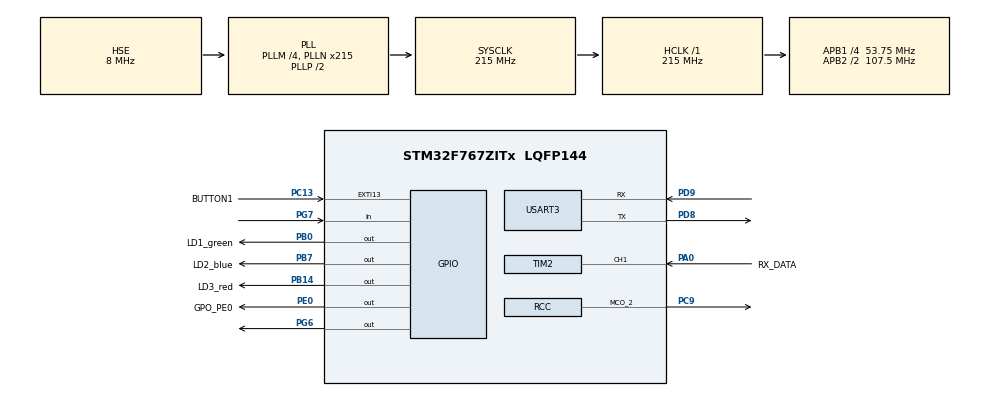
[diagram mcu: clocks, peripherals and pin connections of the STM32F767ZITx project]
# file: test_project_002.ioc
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CORTEX_M7.ART_ACCLERATOR_ENABLE=0
CORTEX_M7.CPU_ICache=Disabled
CORTEX_M7.FlashInterface=TCM_Enabled
CORTEX_M7.PREFETCH_ENABLE=0
Dma.Request0=TIM2_CH1
Dma.TIM2_CH1.0.Direction=DMA_PERIPH_TO_MEMORY
Dma.TIM2_CH1.0.FIFOMode=DMA_FIFOMODE_ENABLE
Dma.TIM2_CH1.0.FIFOThreshold=DMA_FIFO_THRESHOLD_HALFFULL
Dma.TIM2_CH1.0.Instance=DMA1_Stream5
Dma.TIM2_CH1.0.MemBurst=DMA_MBURST_SINGLE
Dma.TIM2_CH1.0.MemDataAlignment=DMA_MDATAALIGN_WORD
Dma.TIM2_CH1.0.MemInc=DMA_MINC_ENABLE
Dma.TIM2_CH1.0.Mode=DMA_NORMAL
Dma.TIM2_CH1.0.PeriphBurst=DMA_PBURST_SINGLE
Dma.TIM2_CH1.0.PeriphDataAlignment=DMA_PDATAALIGN_WORD
Dma.TIM2_CH1.0.PeriphInc=DMA_PINC_DISABLE
Dma.TIM2_CH1.0.Priority=DMA_PRIORITY_VERY_HIGH
Mcu.Family=STM32F7
Mcu.Name=STM32F767ZITx
Mcu.Package=LQFP144
NVIC.DMA1_Stream5_IRQn=true\:0\:0\:false\:false\:true\:false\:true
NVIC.PriorityGroup=NVIC_PRIORITYGROUP_4
NVIC.TIM1_UP_TIM10_IRQn=true\:0\:0\:false\:false\:true\:false\:true
NVIC.TimeBase=TIM1_UP_TIM10_IRQn
NVIC.TimeBaseIP=TIM1
PA0/WKUP.GPIO_Label=RX_DATA
PA0/WKUP.GPIO_Speed=GPIO_SPEED_FREQ_VERY_HIGH
PA0/WKUP.Signal=S_TIM2_CH1_ETR
PA1.GPIO_Mode=GPIO_MODE_AF_PP
PA1.GPIO_PuPd=GPIO_NOPULL
PA1.GPIO_Speed=GPIO_SPEED_FREQ_VERY_HIGH
PA1.Signal=ETH_REF_CLK
PA10.GPIO_Mode=GPIO_MODE_AF_PP
PA10.GPIO_PuPd=GPIO_NOPULL
PA10.GPIO_Speed=GPIO_SPEED_FREQ_VERY_HIGH
PA10.Signal=USB_OTG_FS_ID
PA11.GPIO_Mode=GPIO_MODE_AF_PP
PA11.GPIO_PuPd=GPIO_NOPULL
PA11.GPIO_Speed=GPIO_SPEED_FREQ_VERY_HIGH
PA11.Signal=USB_OTG_FS_DM
PA12.GPIO_Mode=GPIO_MODE_AF_PP
PA12.GPIO_PuPd=GPIO_NOPULL
PA12.GPIO_Speed=GPIO_SPEED_FREQ_VERY_HIGH
PA12.Signal=USB_OTG_FS_DP
PA13.Mode=Serial_Wire
PA13.Signal=SYS_JTMS-SWDIO
PA14.Mode=Serial_Wire
PA14.Signal=SYS_JTCK-SWCLK
PA2.GPIO_Mode=GPIO_MODE_AF_PP
PA2.GPIO_PuPd=GPIO_NOPULL
PA2.GPIO_Speed=GPIO_SPEED_FREQ_VERY_HIGH
PA2.Signal=ETH_MDIO
PA7.GPIO_Mode=GPIO_MODE_AF_PP
PA7.GPIO_PuPd=GPIO_NOPULL
PA7.GPIO_Speed=GPIO_SPEED_FREQ_VERY_HIGH
PA7.Signal=ETH_CRS_DV
PA8.GPIO_Mode=GPIO_MODE_AF_PP
PA8.GPIO_PuPd=GPIO_NOPULL
PA8.GPIO_Speed=GPIO_SPEED_FREQ_VERY_HIGH
PA8.Signal=USB_OTG_FS_SOF
PA9.GPIO_Mode=GPIO_MODE_INPUT
PA9.GPIO_PuPd=GPIO_NOPULL
PA9.Signal=USB_OTG_FS_VBUS
PB0.GPIO_Label=LD1_green
PB0.GPIO_ModeDefaultOutputPP=GPIO_MODE_OUTPUT_PP
PB0.GPIO_PuPd=GPIO_NOPULL
PB0.GPIO_Speed=GPIO_SPEED_FREQ_LOW
PB0.PinState=GPIO_PIN_RESET
PB0.Signal=GPIO_Output
PB13.GPIO_Mode=GPIO_MODE_AF_PP
PB13.GPIO_PuPd=GPIO_NOPULL
PB13.GPIO_Speed=GPIO_SPEED_FREQ_VERY_HIGH
PB13.Signal=ETH_TXD1
PB14.GPIO_Label=LD3_red
PB14.GPIO_ModeDefaultOutputPP=GPIO_MODE_OUTPUT_PP
PB14.GPIO_PuPd=GPIO_NOPULL
PB14.GPIO_Speed=GPIO_SPEED_FREQ_LOW
PB14.PinState=GPIO_PIN_RESET
PB14.Signal=GPIO_Output
PB3.Signal=SYS_JTDO-SWO
PB7.GPIO_FM7=__NULL
PB7.GPIO_Label=LD2_blue
PB7.GPIO_ModeDefaultOutputPP=GPIO_MODE_OUTPUT_PP
PB7.GPIO_PuPd=GPIO_NOPULL
PB7.GPIO_Speed=GPIO_SPEED_FREQ_LOW
PB7.PinState=GPIO_PIN_RESET
PB7.Signal=GPIO_Output
PC1.GPIO_Mode=GPIO_MODE_AF_PP
PC1.GPIO_PuPd=GPIO_NOPULL
PC1.GPIO_Speed=GPIO_SPEED_FREQ_VERY_HIGH
PC1.Signal=ETH_MDC
PC13.GPIO_Label=BUTTON1
PC13.GPIO_ModeDefaultEXTI=GPIO_MODE_IT_RISING
PC13.GPIO_PuPd=GPIO_NOPULL
PC13.Signal=GPXTI13
PC14/OSC32_IN.Mode=LSE-External-Oscillator
PC14/OSC32_IN.Signal=RCC_OSC32_IN
PC15/OSC32_OUT.Mode=LSE-External-Oscillator
PC15/OSC32_OUT.Signal=RCC_OSC32_OUT
PC4.GPIO_Mode=GPIO_MODE_AF_PP
PC4.GPIO_PuPd=GPIO_NOPULL
PC4.GPIO_Speed=GPIO_SPEED_FREQ_VERY_HIGH
PC4.Signal=ETH_RXD0
PC5.GPIO_Mode=GPIO_MODE_AF_PP
PC5.GPIO_PuPd=GPIO_NOPULL
PC5.GPIO_Speed=GPIO_SPEED_FREQ_VERY_HIGH
PC5.Signal=ETH_RXD1
PC9.Mode=Clock-out-2
PC9.Signal=RCC_MCO_2
PD8.GPIO_ModeDefaultPP=GPIO_MODE_AF_PP
PD8.GPIO_PuPd=GPIO_NOPULL
PD8.GPIO_Speed=GPIO_SPEED_FREQ_VERY_HIGH
PD8.Mode=Asynchronous
PD8.Signal=USART3_TX
PD9.GPIO_ModeDefaultPP=GPIO_MODE_AF_PP
PD9.GPIO_PuPd=GPIO_NOPULL
PD9.GPIO_Speed=GPIO_SPEED_FREQ_VERY_HIGH
PD9.Mode=Asynchronous
PD9.Signal=USART3_RX
PE0.GPIO_Label=GPO_PE0
PE0.GPIO_ModeDefaultOutputPP=GPIO_MODE_OUTPUT_PP
PE0.GPIO_PuPd=GPIO_NOPULL
PE0.GPIO_Speed=GPIO_SPEED_FREQ_VERY_HIGH
PE0.PinState=GPIO_PIN_RESET
PE0.Signal=GPIO_Output
PG11.GPIO_Mode=GPIO_MODE_AF_PP
PG11.GPIO_PuPd=GPIO_NOPULL
PG11.GPIO_Speed=GPIO_SPEED_FREQ_VERY_HIGH
PG11.Signal=ETH_TX_EN
PG13.GPIO_Mode=GPIO_MODE_AF_PP
PG13.GPIO_PuPd=GPIO_NOPULL
PG13.GPIO_Speed=GPIO_SPEED_FREQ_VERY_HIGH
PG13.Signal=ETH_TXD0
PG6.GPIO_ModeDefaultOutputPP=GPIO_MODE_OUTPUT_PP
PG6.GPIO_PuPd=GPIO_NOPULL
PG6.GPIO_Speed=GPIO_SPEED_FREQ_LOW
PG6.PinState=GPIO_PIN_RESET
PG6.Signal=GPIO_Output
PG7.GPIO_Mode=GPIO_MODE_INPUT
PG7.GPIO_PuPd=GPIO_NOPULL
PG7.Signal=GPIO_Input
PH0/OSC_IN.Mode=HSE-External-Clock-Source
PH0/OSC_IN.Signal=RCC_OSC_IN
PH1/OSC_OUT.Mode=HSE-External-Clock-Source
PH1/OSC_OUT.Signal=RCC_OSC_OUT
ProjectManager.HeapSize=0x200
ProjectManager.StackSize=0x400
ProjectManager.TargetToolchain=STM32CubeIDE
RCC.AHBFreq_Value=215000000
RCC.APB1CLKDivider=RCC_HCLK_DIV4
RCC.APB1Freq_Value=53750000
RCC.APB1TimFreq_Value=107500000
RCC.APB2CLKDivider=RCC_HCLK_DIV2
RCC.APB2Freq_Value=107500000
RCC.APB2TimFreq_Value=215000000
RCC.CortexFreq_Value=215000000
RCC.HCLKFreq_Value=215000000
RCC.HSE_VALUE=8000000
RCC.HSI_VALUE=16000000
RCC.PLL48CLockSelection=RCC_CLK48SOURCE_PLLSAIP
RCC.PLLM=4
RCC.PLLN=215
RCC.PLLSAIN=96
RCC.PLLSAIP=RCC_PLLSAIP_DIV4
RCC.PLLSourceVirtual=RCC_PLLSOURCE_HSE
RCC.RCC_MCO2Source=RCC_MCO2SOURCE_PLLI2SCLK
RCC.SYSCLKFreq_VALUE=215000000
RCC.SYSCLKSource=RCC_SYSCLKSOURCE_PLLCLK
RCC.USBFreq_Value=48000000
RCC.VCOOutputFreq_Value=430000000
SH.S_TIM2_CH1_ETR.0=TIM2_CH1,Input_Capture1_from_TI1
TIM2.AutoReloadPreload=TIM_AUTORELOAD_PRELOAD_DISABLE
TIM2.Channel-Input_Capture1_from_TI1=TIM_CHANNEL_1
TIM2.Period=0xFFFFFFFF
USART3.VirtualMode-Asynchronous=VM_ASYNC
VP_SYS_VS_tim1.Mode=TIM1
VP_TIM2_VS_ClockSourceINT.Mode=Internal
board=NUCLEO-F767ZI

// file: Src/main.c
/* USER CODE BEGIN Header */
/**
  ******************************************************************************
  * @file           : main.c
  * @brief          : Main program body
  ******************************************************************************
  * @attention
  *
  * <h2><center>&copy; Copyright (c) 2019 STMicroelectronics.
  * All rights reserved.</center></h2>
  *
  * This software component is licensed by ST under Ultimate Liberty license
  * SLA0044, the "License"; You may not use this file except in compliance with
  * the License. You may obtain a copy of the License at:
  *                             www.st.com/SLA0044
  *
  ******************************************************************************
  */
/* USER CODE END Header */

#include "main.h"
#include "dma.h"
#include "tim.h"
#include "usart.h"
#include "gpio.h"

void SystemClock_Config(void);

int main(void)
{

  /* MCU Configuration--------------------------------------------------------*/

  /* Reset of all peripherals, Initializes the Flash interface and the Systick. */
  HAL_Init();

  /* Configure the system clock */
  SystemClock_Config();

  /* Initialize all configured peripherals */
  MX_GPIO_Init();
  MX_DMA_Init();
  MX_USART3_UART_Init();
  MX_TIM2_Init();

  /* Infinite loop */
  /* USER CODE BEGIN WHILE */

  read_tim2_ch1_capture_dma();

  while (1)
  {
    /* USER CODE END WHILE */

  }
}

void SystemClock_Config(void)
{
  RCC_OscInitTypeDef RCC_OscInitStruct = {0};
  RCC_ClkInitTypeDef RCC_ClkInitStruct = {0};
  RCC_PeriphCLKInitTypeDef PeriphClkInitStruct = {0};

  /** Configure LSE Drive Capability
  */
  HAL_PWR_EnableBkUpAccess();
  /** Configure the main internal regulator output voltage
  */
  __HAL_RCC_PWR_CLK_ENABLE();
  __HAL_PWR_VOLTAGESCALING_CONFIG(PWR_REGULATOR_VOLTAGE_SCALE1);
  /** Initializes the CPU, AHB and APB busses clocks
  */
  RCC_OscInitStruct.OscillatorType = RCC_OSCILLATORTYPE_HSE;
  RCC_OscInitStruct.HSEState = RCC_HSE_BYPASS;
  RCC_OscInitStruct.PLL.PLLState = RCC_PLL_ON;
  RCC_OscInitStruct.PLL.PLLSource = RCC_PLLSOURCE_HSE;
  RCC_OscInitStruct.PLL.PLLM = 4;
  RCC_OscInitStruct.PLL.PLLN = 215;
  RCC_OscInitStruct.PLL.PLLP = RCC_PLLP_DIV2;
  RCC_OscInitStruct.PLL.PLLQ = 2;
  if (HAL_RCC_OscConfig(&RCC_OscInitStruct) != HAL_OK)
  {
    Error_Handler();
  }
  /** Activate the Over-Drive mode
  */
  if (HAL_PWREx_EnableOverDrive() != HAL_OK)
  {
    Error_Handler();
  }
  /** Initializes the CPU, AHB and APB busses clocks
  */
  RCC_ClkInitStruct.ClockType = RCC_CLOCKTYPE_HCLK|RCC_CLOCKTYPE_SYSCLK
                              |RCC_CLOCKTYPE_PCLK1|RCC_CLOCKTYPE_PCLK2;
  RCC_ClkInitStruct.SYSCLKSource = RCC_SYSCLKSOURCE_PLLCLK;
  RCC_ClkInitStruct.AHBCLKDivider = RCC_SYSCLK_DIV1;
  RCC_ClkInitStruct.APB1CLKDivider = RCC_HCLK_DIV4;
  RCC_ClkInitStruct.APB2CLKDivider = RCC_HCLK_DIV2;

  if (HAL_RCC_ClockConfig(&RCC_ClkInitStruct, FLASH_LATENCY_7) != HAL_OK)
  {
    Error_Handler();
  }
  PeriphClkInitStruct.PeriphClockSelection = RCC_PERIPHCLK_PLLI2S|RCC_PERIPHCLK_USART3;
  PeriphClkInitStruct.PLLI2S.PLLI2SN = 192;
  PeriphClkInitStruct.PLLI2S.PLLI2SP = RCC_PLLP_DIV2;
  PeriphClkInitStruct.PLLI2S.PLLI2SR = 2;
  PeriphClkInitStruct.PLLI2S.PLLI2SQ = 2;
  PeriphClkInitStruct.PLLI2SDivQ = 1;
  PeriphClkInitStruct.Usart3ClockSelection = RCC_USART3CLKSOURCE_PCLK1;
  if (HAL_RCCEx_PeriphCLKConfig(&PeriphClkInitStruct) != HAL_OK)
  {
    Error_Handler();
  }
  HAL_RCC_MCOConfig(RCC_MCO2, RCC_MCO2SOURCE_PLLI2SCLK, RCC_MCODIV_1);
}

void HAL_TIM_PeriodElapsedCallback(TIM_HandleTypeDef *htim)
{
  if (htim->Instance == TIM1) {
    HAL_IncTick();
  }
}

void Error_Handler(void)
{
}

/************************ (C) COPYRIGHT STMicroelectronics *****END OF FILE****/
